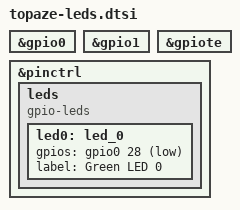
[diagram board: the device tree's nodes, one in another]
/* ============================================================
 * This file is the overlay DTS for topaze that define the GPIOs
 *
 * We describe here the peripherals configuration, and so on...
 *
 * l.heywang
 * 18/02/2025
 *
 * ============================================================
 */

// ============================================================
// GPIO AND PINCTRL
// ============================================================
// Enable GPIO controllers
&gpio0 {
    status = "okay";
};

&gpio1 {
    status = "okay";
};

&gpiote {
    status = "okay";
};

// Virtual device that map physical pins to names
&pinctrl {
    leds {
		compatible = "gpio-leds";
		led0: led_0 {
			gpios = <&gpio0 28 GPIO_ACTIVE_LOW>;
			label = "Green LED 0";
		};
		// led1: led_1 {
		// 	gpios = <&gpio0 29 GPIO_ACTIVE_LOW>;
		// 	label = "Green LED 1";
		// };
		// led2: led_2 {
		// 	gpios = <&gpio0 30 GPIO_ACTIVE_LOW>;
		// 	label = "Green LED 2";
		// };
		// led3: led_3 {
		// 	gpios = <&gpio0 31 GPIO_ACTIVE_LOW>;
		// 	label = "Green LED 3";
		// };
	};
};

